# STM32WL5x_CM0P register map
File version: 1.9
CPU: CM0 r0p1, little endian, MPU, no FPU, 4 interrupt priority bits
Registers are 32-bit, read-write, reset 0x0 unless marked. A register's access mark holds for its fields unless they carry their own. Offsets are from the block's base; [hi:lo] are bit positions; {n}, {i} and the like mark numbered series.

## ADC — Analog to digital convertor
Base 0x40012400
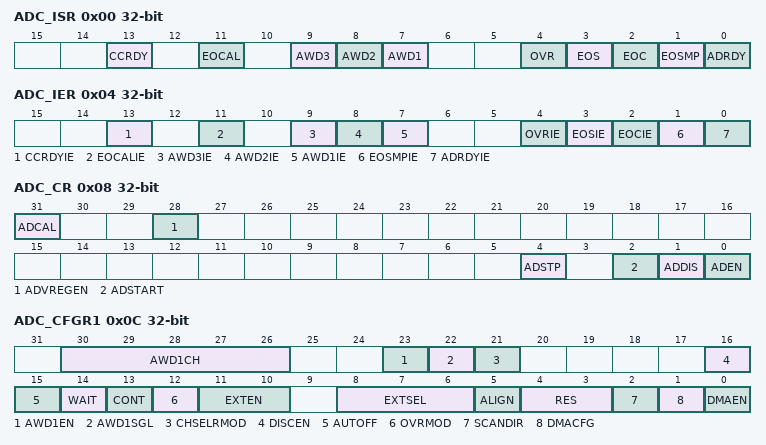
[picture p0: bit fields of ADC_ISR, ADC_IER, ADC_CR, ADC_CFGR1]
0x00 ADC_ISR — ADC interrupt and status register
  [13] CCRDY, [11] EOCAL, [9] AWD3, [8] AWD2, [7] AWD1, [4] OVR, [3] EOS, [2] EOC, [1] EOSMP, [0] ADRDY
0x04 ADC_IER — ADC interrupt enable register
  [13] CCRDYIE, [11] EOCALIE, [9] AWD3IE, [8] AWD2IE, [7] AWD1IE, [4] OVRIE, [3] EOSIE, [2] EOCIE, [1] EOSMPIE, [0] ADRDYIE
0x08 ADC_CR — ADC control register
  [31] ADCAL, [28] ADVREGEN, [4] ADSTP, [2] ADSTART, [1] ADDIS, [0] ADEN
0x0C ADC_CFGR1 — ADC configuration register 1
  [30:26] AWD1CH, [23] AWD1EN, [22] AWD1SGL, [21] CHSELRMOD, [16] DISCEN, [15] AUTOFF, [14] WAIT, [13] CONT, [12] OVRMOD, [11:10] EXTEN, [8:6] EXTSEL, [5] ALIGN, [4:3] RES, [2] SCANDIR, [1] DMACFG, [0] DMAEN
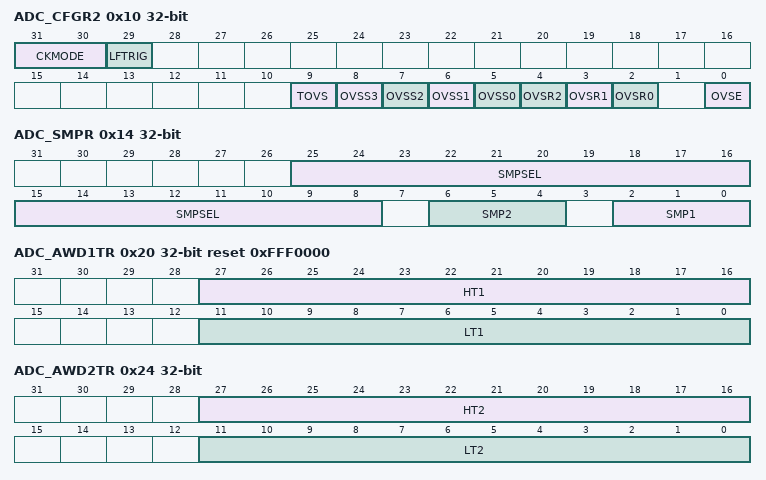
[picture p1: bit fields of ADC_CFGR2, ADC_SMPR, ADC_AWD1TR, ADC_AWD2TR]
0x10 ADC_CFGR2 — ADC configuration register 2
  [31:30] CKMODE, [29] LFTRIG, [9] TOVS, [n+5] OVSS{n} (n=0..3), [4] OVSR2, [3] OVSR1, [2] OVSR0, [0] OVSE
0x14 ADC_SMPR — ADC sampling time register
  [25:8] SMPSEL, [6:4] SMP2, [2:0] SMP1
0x20 ADC_AWD1TR reset 0xFFF0000 — ADC watchdog threshold register
  [27:16] HT1, [11:0] LT1
0x24 ADC_AWD2TR — ADC watchdog threshold register
  [27:16] HT2, [11:0] LT2
0x28 ADC_CHSELR0 — channel selection register
  [17:0] CHSEL
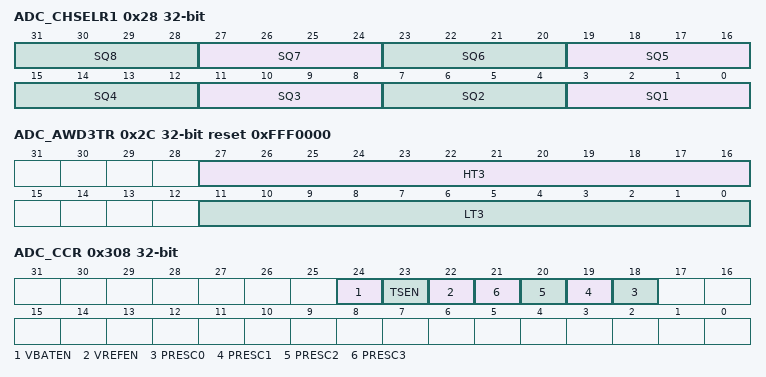
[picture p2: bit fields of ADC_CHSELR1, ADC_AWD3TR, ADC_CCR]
0x28 ADC_CHSELR1 (alternate view of ADC_CHSELR0) — channel selection register
  [4n-1:4n-4] SQ{n} (n=1..8)
0x2C ADC_AWD3TR reset 0xFFF0000 — ADC watchdog threshold register
  [27:16] HT3, [11:0] LT3
0x40 ADC_DR ro — ADC data register
  [15:0] DATA
0xA0 ADC_AWD2CR — ADC Analog Watchdog 2 Configuration register
  [17:0] AWD2CH
0xA4 ADC_AWD3CR — ADC Analog Watchdog 3 Configuration register
  [17:0] AWD3CH
0xB4 ADC_CALFACT — ADC Calibration factor
  [6:0] CALFACT
0x308 ADC_CCR — ADC common configuration register
  [24] VBATEN, [23] TSEN, [22] VREFEN, [n+18] PRESC{n} (n=0..3)

## AES — Advanced encryption standard hardware accelerator 1
Base 0x58001800
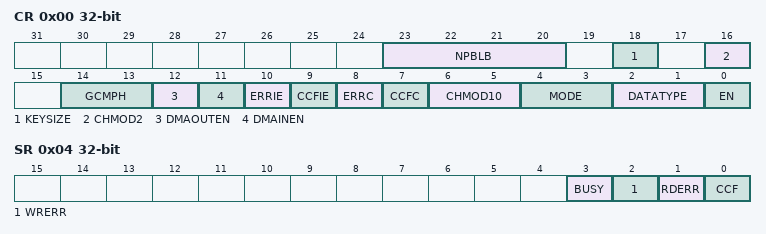
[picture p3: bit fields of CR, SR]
0x00 CR — control register
  [23:20] NPBLB — Number of padding bytes in last block of payload
  [18] KEYSIZE — Key size selection
  [16] CHMOD2 — AES chaining mode Bit2
  [14:13] GCMPH — Used only for GCM, CCM and GMAC algorithms and has no effect when other algorithms are selected
  [12] DMAOUTEN — Enable DMA management of data output phase
  [11] DMAINEN — Enable DMA management of data input phase
  [10] ERRIE — Error interrupt enable
  [9] CCFIE — CCF flag interrupt enable
  [8] ERRC — Error clear
  [7] CCFC — Computation Complete Flag Clear
  [6:5] CHMOD10 — AES chaining mode Bit1 Bit0
  [4:3] MODE — AES operating mode
  [2:1] DATATYPE — Data type selection (for data in and data out to/from the cryptographic block)
  [0] EN — AES enable
0x04 SR ro — status register
  [3] BUSY — Busy flag
  [2] WRERR — Write error flag
  [1] RDERR — Read error flag
  [0] CCF — Computation complete flag
0x08 DINR — data input register
  [31:0] AES_DINR — Data Input Register
0x0C DOUTR ro — data output register
  [31:0] AES_DOUTR — Data output register
0x10 KEYR0 wo — key register 0
  [31:0] AES_KEYR0 — Data Output Register (LSB key [31:0])
0x14 KEYR1 wo — key register 1
  [31:0] AES_KEYR1 — AES key register (key [63:32])
0x18 KEYR2 wo — key register 2
  [31:0] AES_KEYR2 — AES key register (key [95:64])
0x1C KEYR3 wo — key register 3
  [31:0] AES_KEYR3 — AES key register (MSB key [127:96])
0x20 IVR0 — initialization vector register 0
  [31:0] AES_IVR0 — initialization vector register (LSB IVR [31:0])
0x24 IVR1 — initialization vector register 1
  [31:0] AES_IVR1 — Initialization Vector Register (IVR [63:32])
0x28 IVR2 — initialization vector register 2
  [31:0] AES_IVR2 — Initialization Vector Register (IVR [95:64])
0x2C IVR3 — initialization vector register 3
  [31:0] AES_IVR3 — Initialization Vector Register (MSB IVR [127:96])
{0x20+4i} KEYR{i} wo (i=4..7) — key register {i}
  [31:0] AES_KEYR{i} — AES key register (MSB key [{32i+31}:{32i}])
{0x40+4i} SUSP{i}R (i=0..7) — AES suspend register {i}
  [31:0] AES_SUSP{i}R
